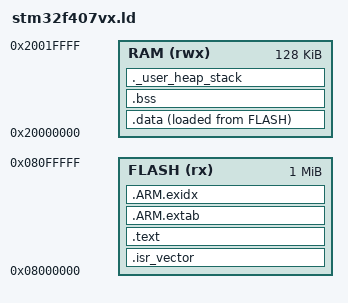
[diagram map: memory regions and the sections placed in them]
/* STM32F407Vx — Flash 1MB @0x08000000, SRAM 128KB (DMA-visible) @0x20000000 */
_estack = ORIGIN(RAM) + LENGTH(RAM);

MEMORY
{
  FLASH (rx)  : ORIGIN = 0x08000000, LENGTH = 1024K
  RAM   (rwx) : ORIGIN = 0x20000000, LENGTH = 128K
}

_Min_Heap_Size = 0x400;
_Min_Stack_Size = 0x8000;

ENTRY(Reset_Handler)

SECTIONS
{
  .isr_vector :
  {
    KEEP(*(.isr_vector))
  } > FLASH

  .text :
  {
    *(.text*)
    *(.rodata*)
    KEEP(*(.init))
    KEEP(*(.fini))
    *(.glue_7)
    *(.glue_7t)
  } > FLASH

  .ARM.extab : { *(.ARM.extab* .gnu.linkonce.armextab.*) } > FLASH
  .ARM.exidx : { __exidx_start = .; *(.ARM.exidx*) __exidx_end = .; } > FLASH

  _sidata = LOADADDR(.data);

  .data :
  {
    _sdata = .;
    *(.data*)
    _edata = .;
  } > RAM AT > FLASH

  .bss :
  {
    _sbss = .;
    *(.bss*)
    *(COMMON)
    _ebss = .;
  } > RAM

  ._user_heap_stack :
  {
    . = ALIGN(8);
    PROVIDE(end = .);
    PROVIDE(_end = .);
    . = . + _Min_Heap_Size;
    . = . + _Min_Stack_Size;
    . = ALIGN(8);
  } > RAM
}
